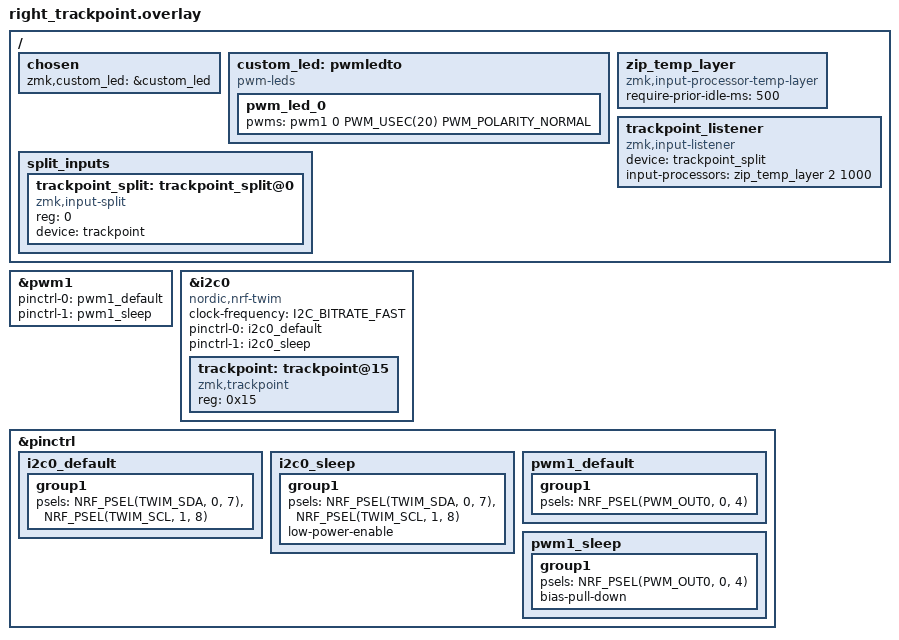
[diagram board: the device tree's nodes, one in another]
/*
*
* Copyright (c) 2025 ZitaoTech
* SPDX-License-Identifier: MIT
*
*/

#include <zephyr/dt-bindings/input/input-event-codes.h>

/ {
    chosen {
        zmk,custom_led = &custom_led;
    };
    custom_led: pwmledto{
        compatible = "pwm-leds";
        pwm_led_0 {
            pwms = <&pwm1 0 PWM_USEC(20) PWM_POLARITY_NORMAL>;
        };
    };

    /* Auto-mouse layer input processor */
    zip_temp_layer: zip_temp_layer {
        compatible = "zmk,input-processor-temp-layer";
        #input-processor-cells = <2>;
        require-prior-idle-ms = <500>;
    };

};

&pwm1 {
    status = "okay";
    pinctrl-0 = <&pwm1_default>;
    pinctrl-1 = <&pwm1_sleep>;
    pinctrl-names = "default", "sleep";
};

&i2c0 {
    status = "okay";
    compatible = "nordic,nrf-twim";
    clock-frequency = <I2C_BITRATE_FAST>; 
    pinctrl-0 = <&i2c0_default>;
    pinctrl-1 = <&i2c0_sleep>;
    pinctrl-names = "default", "sleep";

    trackpoint:trackpoint@15 {
        compatible = "zmk,trackpoint";
        reg = <0x15>;
        status = "okay";
    };
};

/ {
    split_inputs {
        #address-cells = <1>;
        #size-cells = <0>;

        /* BB Trackball */
        trackpoint_split: trackpoint_split@0 {
            compatible = "zmk,input-split";
            reg = <0>;
        };

    };

    /* Listeners - Auto switch to mouse layer on trackpoint movement */
    trackpoint_listener: trackpoint_listener {
        compatible = "zmk,input-listener";
        status = "okay";
        device = <&trackpoint_split>;
        input-processors = <&zip_temp_layer 2 1000>;  /* Layer 2 (MOUSE), 1000ms timeout */
    };

};


&trackpoint_split {
    device = <&trackpoint>;
};

&pinctrl {
        i2c0_default: i2c0_default {
        group1 {
            psels = <NRF_PSEL(TWIM_SDA, 0, 7)>,
                <NRF_PSEL(TWIM_SCL, 1, 8)>;
        };
    };

    i2c0_sleep: i2c0_sleep {
        group1 {
            psels = <NRF_PSEL(TWIM_SDA, 0, 7)>,
                <NRF_PSEL(TWIM_SCL, 1, 8)>;
            low-power-enable;
        };
    };
    pwm1_default: pwm1_default {
        group1 {
            psels = <NRF_PSEL(PWM_OUT0, 0, 4)>; // Custom led
        };
    };

    pwm1_sleep: pwm1_sleep {
        group1 {
            psels = <NRF_PSEL(PWM_OUT0, 0, 4)>;
            bias-pull-down;
        };
    };
};

